# PIC32MK0256MCJ048 register map
Vendor: Microchip
Registers are 32-bit, read-write, reset 0x0 unless marked. A register's access mark holds for its fields unless they carry their own. Addresses are absolute, and some are shared; only a register's first bit layout is shown; [hi:lo] are bit positions; {n}, {i} and the like mark numbered series.

## CAN1
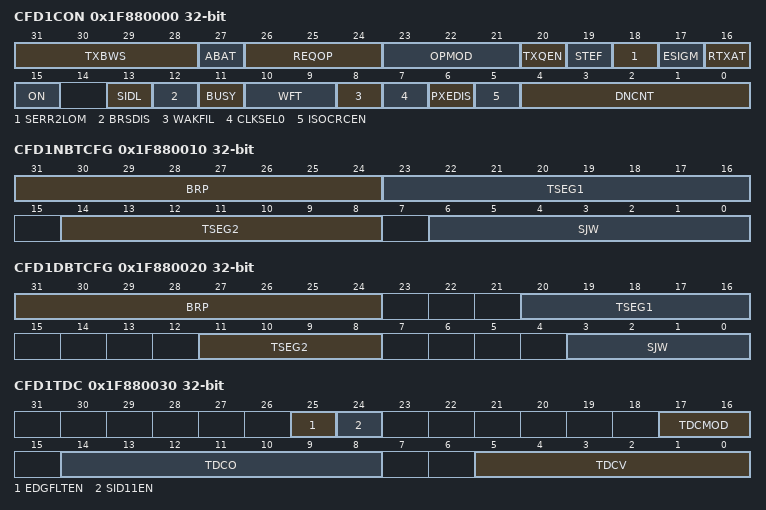
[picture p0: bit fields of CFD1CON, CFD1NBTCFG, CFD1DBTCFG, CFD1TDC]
0x1F880000 CFD1CON reset not defined — (power-on value xxxx01001000xxxx0-0x0xxxxxx00000)
  [31:28] TXBWS
  [27] ABAT — (can only be set)
  [26:24] REQOP
  [23:21] OPMOD ro
  [20] TXQEN
  [19] STEF
  [18] SERR2LOM
  [17] ESIGM
  [16] RTXAT
  [15] ON
  [13] SIDL
  [12] BRSDIS
  [11] BUSY ro
  [10:9] WFT
  [8] WAKFIL
  [7] CLKSEL0
  [6] PXEDIS
  [5] ISOCRCEN
  [4:0] DNCNT
0x1F880010 CFD1NBTCFG reset not defined — (power-on value xxxxxxxxxxxxxxxx-xxxxxxx-xxxxxxx)
  [31:24] BRP, [23:16] TSEG1, [14:8] TSEG2, [6:0] SJW
0x1F880020 CFD1DBTCFG reset not defined — (power-on value xxxxxxxx---xxxxx----xxxx----xxxx)
  [31:24] BRP, [20:16] TSEG1, [11:8] TSEG2, [3:0] SJW
0x1F880030 CFD1TDC reset not defined — (power-on value ------xx------xx-xxxxxxx--xxxxxx)
  [25] EDGFLTEN, [24] SID11EN, [17:16] TDCMOD, [14:8] TDCO, [5:0] TDCV
0x1F880040 CFD1TBC reset not defined — (power-on value xxxxxxxxxxxxxxxxxxxxxxxxxxxxxxxx)
  [31:0] TBC
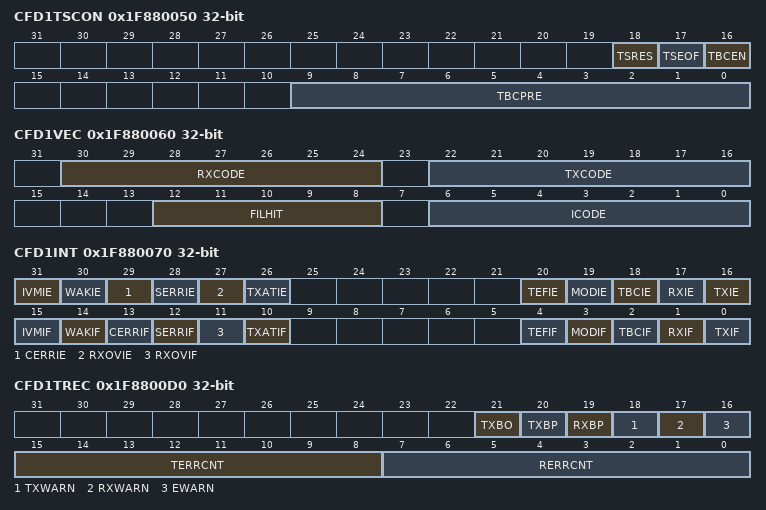
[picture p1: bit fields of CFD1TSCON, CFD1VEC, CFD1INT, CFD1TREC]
0x1F880050 CFD1TSCON reset not defined — (power-on value -------------xxx------xxxxxxxxxx)
  [18] TSRES, [17] TSEOF, [16] TBCEN, [9:0] TBCPRE
0x1F880060 CFD1VEC reset not defined — (power-on value 0xxxxxxx0xxxxxxx0000000001000000)
  [30:24] RXCODE, [22:16] TXCODE, [12:8] FILHIT ro, [6:0] ICODE ro
0x1F880070 CFD1INT reset not defined — (power-on value 00000x--000x000000000x--000x0000)
  [31] IVMIE, [30] WAKIE, [29] CERRIE, [28] SERRIE, [27] RXOVIE, [26] TXATIE, [20] TEFIE, [19] MODIE, [18] TBCIE, [17] RXIE, [16] TXIE, [15] IVMIF, [14] WAKIF, [13] CERRIF, [12] SERRIF, [11] RXOVIF, [10] TXATIF, [4] TEFIF, [3] MODIF, [2] TBCIF, [1] RXIF, [0] TXIF
0x1F880080 CFD1RXIF reset not defined — (power-on value xxxxxxxxxxxxxxxxxxxxxxxxxxxxxxx-)
  [31:1] RFIF
0x1F880090 CFD1TXIF reset not defined — (power-on value xxxxxxxxxxxxxxxxxxxxxxxxxxxxxxxx)
  [31:0] TFIF
0x1F8800A0 CFD1RXOVIF reset not defined — (power-on value xxxxxxxxxxxxxxxxxxxxxxxxxxxxxxx-)
  [31:1] RFOVIF
0x1F8800B0 CFD1TXATIF reset not defined — (power-on value xxxxxxxxxxxxxxxxxxxxxxxxxxxxxxxx)
  [31:0] TFATIF
0x1F8800C0 CFD1TXREQ reset not defined — (power-on value xxxxxxxxxxxxxxxxxxxxxxxxxxxxxxxx)
  [31:0] TXREQ
0x1F8800D0 CFD1TREC ro
  [21] TXBO, [20] TXBP, [19] RXBP, [18] TXWARN, [17] RXWARN, [16] EWARN, [15:8] TERRCNT, [7:0] RERRCNT
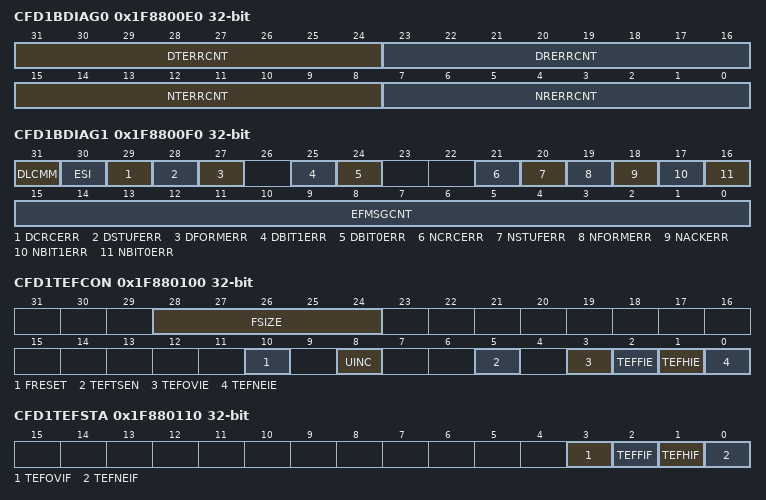
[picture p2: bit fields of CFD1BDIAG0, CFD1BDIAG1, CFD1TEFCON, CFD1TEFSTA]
0x1F8800E0 CFD1BDIAG0 reset not defined — (power-on value xxxxxxxxxxxxxxxxxxxxxxxxxxxxxxxx)
  [31:24] DTERRCNT, [23:16] DRERRCNT, [15:8] NTERRCNT, [7:0] NRERRCNT
0x1F8800F0 CFD1BDIAG1 reset not defined — (power-on value xxxxx-xx--xxxxxxxxxxxxxxxxxxxxxx)
  [31] DLCMM, [30] ESI, [29] DCRCERR, [28] DSTUFERR, [27] DFORMERR, [25] DBIT1ERR, [24] DBIT0ERR, [21] NCRCERR, [20] NSTUFERR, [19] NFORMERR, [18] NACKERR, [17] NBIT1ERR, [16] NBIT0ERR, [15:0] EFMSGCNT
0x1F880100 CFD1TEFCON reset not defined — (power-on value ---xxxxx-------------x-x--x-xxxx)
  [28:24] FSIZE, [10] FRESET, [8] UINC, [5] TEFTSEN, [3] TEFOVIE, [2] TEFFIE, [1] TEFHIE, [0] TEFNEIE
0x1F880110 CFD1TEFSTA reset not defined — (power-on value ----------------------------xxxx)
  [3] TEFOVIF, [2] TEFFIF, [1] TEFHIF, [0] TEFNEIF
0x1F880120 CFD1TEFUA reset not defined — (power-on value xxxxxxxxxxxxxxxxxxxxxxxxxxxxxxxx)
  [31:0] TEFUA
0x1F880130 CFD1FIFOBA reset not defined — (power-on value xxxxxxxxxxxxxxxxxxxxxxxxxxxxxxxx)
  [31:0] FIFOBA
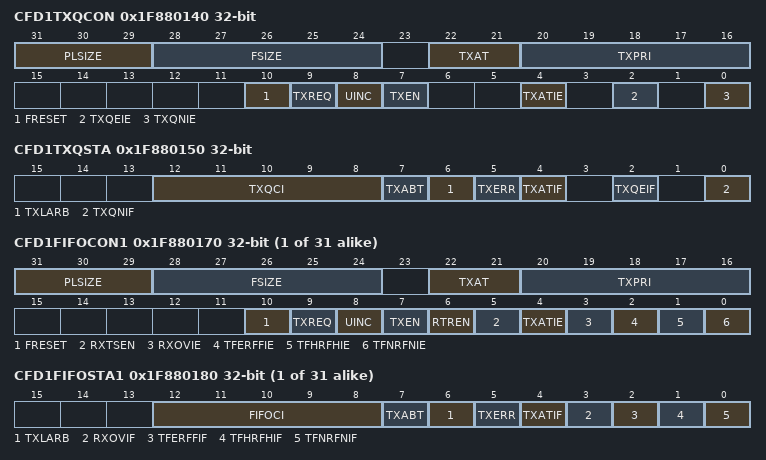
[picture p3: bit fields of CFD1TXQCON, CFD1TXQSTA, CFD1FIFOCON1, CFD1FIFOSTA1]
0x1F880140 CFD1TXQCON reset not defined — (power-on value xxxxxxxx-xxxxxxx-----xxxx--x-x-x)
  [31:29] PLSIZE, [28:24] FSIZE, [22:21] TXAT, [20:16] TXPRI, [10] FRESET, [9] TXREQ, [8] UINC, [7] TXEN, [4] TXATIE, [2] TXQEIE, [0] TXQNIE
0x1F880150 CFD1TXQSTA reset not defined — (power-on value -------------------xxxxxxxxx-x-x)
  [12:8] TXQCI, [7] TXABT, [6] TXLARB, [5] TXERR, [4] TXATIF, [2] TXQEIF, [0] TXQNIF
0x1F880160 CFD1TXQUA reset not defined — (power-on value xxxxxxxxxxxxxxxxxxxxxxxxxxxxxxxx)
  [31:0] TXQUA
{0x1F880140+0x30*i} CFD1FIFOCON{i} reset not defined (i=1..31) — (power-on value xxxxxxxx-xxxxxxx-----xxxxxxxxxxx)
  [31:29] PLSIZE, [28:24] FSIZE, [22:21] TXAT, [20:16] TXPRI, [10] FRESET, [9] TXREQ, [8] UINC, [7] TXEN, [6] RTREN, [5] RXTSEN, [4] TXATIE, [3] RXOVIE, [2] TFERFFIE, [1] TFHRFHIE, [0] TFNRFNIE
{0x1F880150+0x30*i} CFD1FIFOSTA{i} reset not defined (i=1..31) — (power-on value -------------------xxxxxxxxxxxxx)
  [12:8] FIFOCI, [7] TXABT, [6] TXLARB, [5] TXERR, [4] TXATIF, [3] RXOVIF, [2] TFERFFIF, [1] TFHRFHIF, [0] TFNRFNIF
{0x1F880160+0x30*i} CFD1FIFOUA{i} reset not defined (i=1..31) — (power-on value xxxxxxxxxxxxxxxxxxxxxxxxxxxxxxxx)
  [31:0] FIFOUA
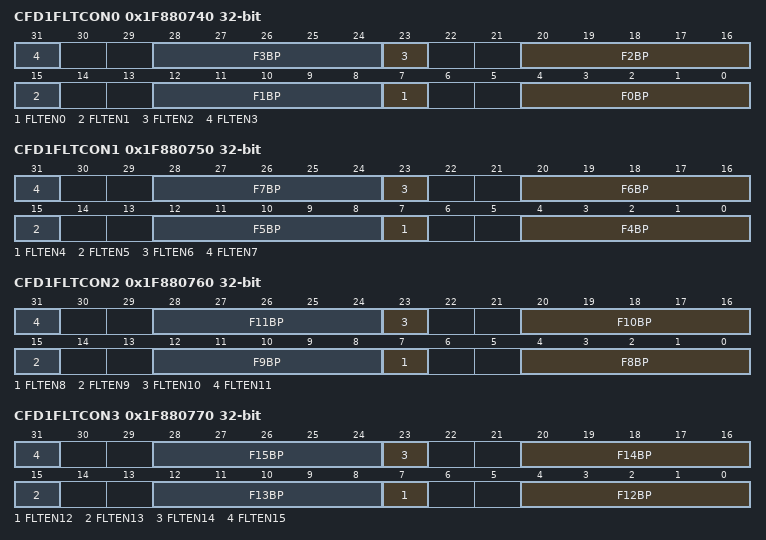
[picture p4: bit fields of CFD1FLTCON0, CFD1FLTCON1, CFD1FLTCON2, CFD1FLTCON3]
0x1F880740 CFD1FLTCON0 reset not defined — (power-on value x--xxxxxx--xxxxxx--xxxxxx--xxxxx)
  [8n+7] FLTEN{n} (n=0..3), [8n+4:8n] F{n}BP (n=0..3)
0x1F880750 CFD1FLTCON1 reset not defined — (power-on value x--xxxxxx--xxxxxx--xxxxxx--xxxxx)
  [8n-25] FLTEN{n} (n=4..7), [8n-28:8n-32] F{n}BP (n=4..7)
0x1F880760 CFD1FLTCON2 reset not defined — (power-on value x--xxxxxx--xxxxxx--xxxxxx--xxxxx)
  [8n-57] FLTEN{n} (n=8..11), [8n-60:8n-64] F{n}BP (n=8..11)
0x1F880770 CFD1FLTCON3 reset not defined — (power-on value x--xxxxxx--xxxxxx--xxxxxx--xxxxx)
  [8n-89] FLTEN{n} (n=12..15), [8n-92:8n-96] F{n}BP (n=12..15)
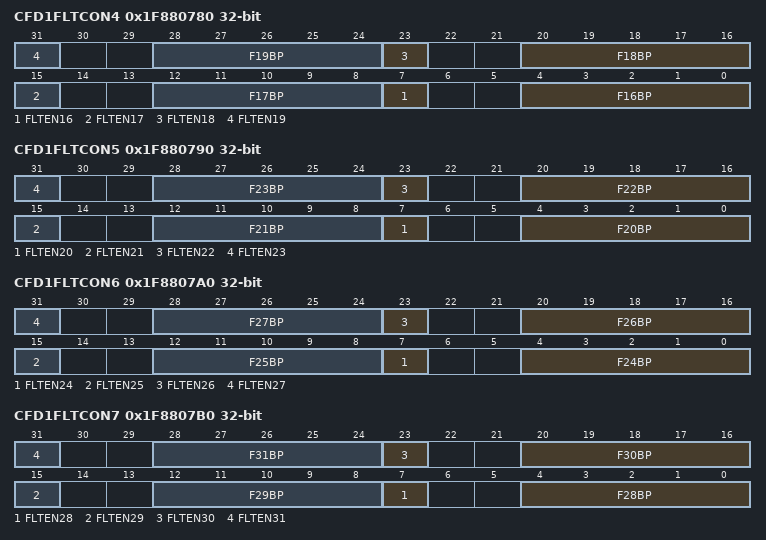
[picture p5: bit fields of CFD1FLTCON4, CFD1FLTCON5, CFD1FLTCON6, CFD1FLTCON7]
0x1F880780 CFD1FLTCON4 reset not defined — (power-on value x--xxxxxx--xxxxxx--xxxxxx--xxxxx)
  [8n-121] FLTEN{n} (n=16..19), [8n-124:8n-128] F{n}BP (n=16..19)
0x1F880790 CFD1FLTCON5 reset not defined — (power-on value x--xxxxxx--xxxxxx--xxxxxx--xxxxx)
  [8n-153] FLTEN{n} (n=20..23), [8n-156:8n-160] F{n}BP (n=20..23)
0x1F8807A0 CFD1FLTCON6 reset not defined — (power-on value x--xxxxxx--xxxxxx--xxxxxx--xxxxx)
  [8n-185] FLTEN{n} (n=24..27), [8n-188:8n-192] F{n}BP (n=24..27)
0x1F8807B0 CFD1FLTCON7 reset not defined — (power-on value x--xxxxxx--xxxxxx--xxxxxx--xxxxx)
  [8n-217] FLTEN{n} (n=28..31), [8n-220:8n-224] F{n}BP (n=28..31)
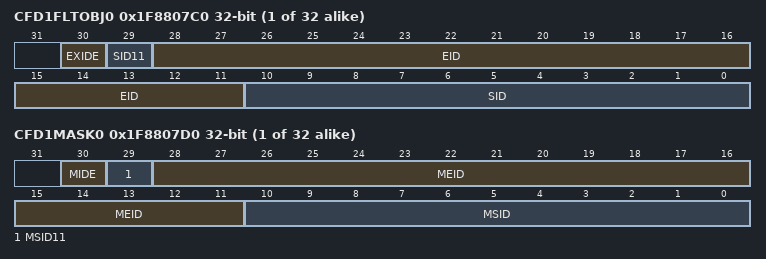
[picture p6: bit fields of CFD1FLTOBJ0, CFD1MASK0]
{0x1F8807C0+0x20*i} CFD1FLTOBJ{i} reset not defined (i=0..31) — (power-on value -xxxxxxxxxxxxxxxxxxxxxxxxxxxxxxx)
  [30] EXIDE, [29] SID11, [28:11] EID, [10:0] SID
{0x1F8807D0+0x20*i} CFD1MASK{i} reset not defined (i=0..31) — (power-on value -xxxxxxxxxxxxxxxxxxxxxxxxxxxxxxx)
  [30] MIDE, [29] MSID11, [28:11] MEID, [10:0] MSID
